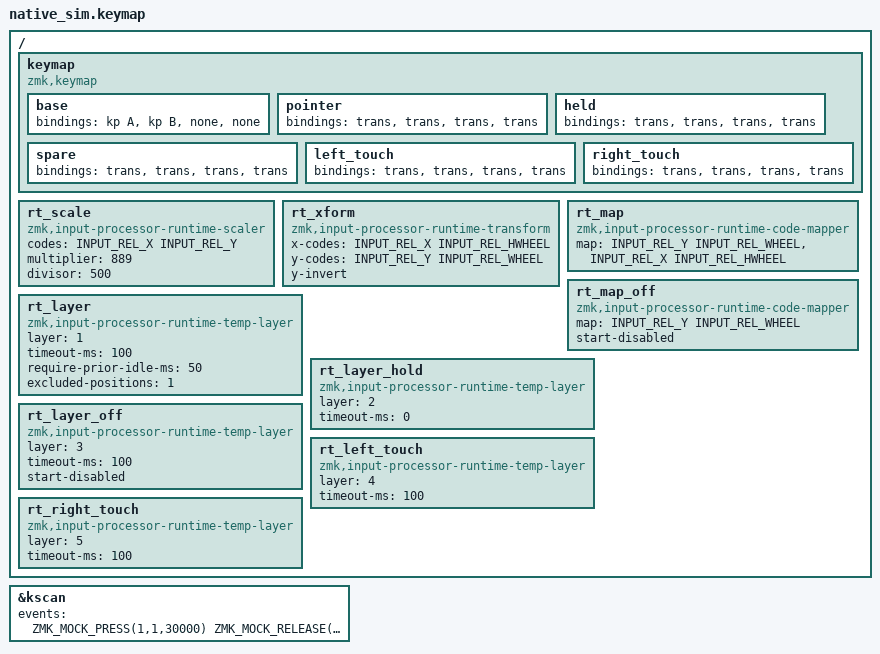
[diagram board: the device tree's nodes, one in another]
/*
 * Copyright (c) 2026 amgskobo
 * SPDX-License-Identifier: MIT
 *
 * One instance of each driver in each starting state, for the driver
 * self-tests. The keymap gives the temp layers somewhere to go: position 0
 * presses a key, position 1 presses a key and is excluded, position 3 is empty.
 */

#include <behaviors.dtsi>
#include <dt-bindings/zmk/keys.h>
#include <dt-bindings/zmk/kscan_mock.h>
#include <zephyr/dt-bindings/input/input-event-codes.h>

/ {
    keymap {
        compatible = "zmk,keymap";

        base {
            bindings = <&kp A &kp B &none &none>;
        };

        pointer {
            bindings = <&trans &trans &trans &trans>;
        };

        held {
            bindings = <&trans &trans &trans &trans>;
        };

        spare {
            bindings = <&trans &trans &trans &trans>;
        };

        left_touch {
            bindings = <&trans &trans &trans &trans>;
        };

        right_touch {
            bindings = <&trans &trans &trans &trans>;
        };
    };

    rt_scale: rt_scale {
        compatible = "zmk,input-processor-runtime-scaler";
        #input-processor-cells = <0>;
        codes = <INPUT_REL_X INPUT_REL_Y>;
        multiplier = <889>;
        divisor = <500>;
    };

    rt_xform: rt_xform {
        compatible = "zmk,input-processor-runtime-transform";
        #input-processor-cells = <0>;
        x-codes = <INPUT_REL_X INPUT_REL_HWHEEL>;
        y-codes = <INPUT_REL_Y INPUT_REL_WHEEL>;
        y-invert;
    };

    rt_map: rt_map {
        compatible = "zmk,input-processor-runtime-code-mapper";
        #input-processor-cells = <0>;
        map = <INPUT_REL_Y INPUT_REL_WHEEL>, <INPUT_REL_X INPUT_REL_HWHEEL>;
    };

    rt_map_off: rt_map_off {
        compatible = "zmk,input-processor-runtime-code-mapper";
        #input-processor-cells = <0>;
        map = <INPUT_REL_Y INPUT_REL_WHEEL>;
        start-disabled;
    };

    rt_layer: rt_layer {
        compatible = "zmk,input-processor-runtime-temp-layer";
        #input-processor-cells = <0>;
        layer = <1>;
        timeout-ms = <100>;
        require-prior-idle-ms = <50>;
        excluded-positions = <1>;
    };

    rt_layer_hold: rt_layer_hold {
        compatible = "zmk,input-processor-runtime-temp-layer";
        #input-processor-cells = <0>;
        layer = <2>;
        timeout-ms = <0>;
    };

    rt_layer_off: rt_layer_off {
        compatible = "zmk,input-processor-runtime-temp-layer";
        #input-processor-cells = <0>;
        layer = <3>;
        timeout-ms = <100>;
        start-disabled;
    };

    rt_left_touch: rt_left_touch {
        compatible = "zmk,input-processor-runtime-temp-layer";
        #input-processor-cells = <0>;
        layer = <4>;
        timeout-ms = <100>;
    };

    rt_right_touch: rt_right_touch {
        compatible = "zmk,input-processor-runtime-temp-layer";
        #input-processor-cells = <0>;
        layer = <5>;
        timeout-ms = <100>;
    };
};

/* Nothing is scanned. The one event ends the process if the tests ever hang. */
&kscan {
    events = <ZMK_MOCK_PRESS(1,1,30000) ZMK_MOCK_RELEASE(1,1,10)>;
};
